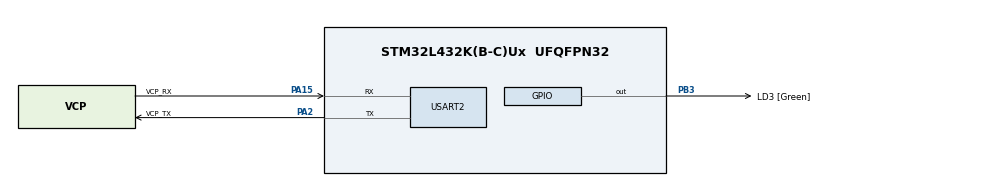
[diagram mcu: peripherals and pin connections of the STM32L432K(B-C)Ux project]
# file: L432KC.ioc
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FREERTOS.Tasks01=defaultTask,0,128,StartDefaultTask,Default,NULL,Dynamic,NULL,NULL;myTask02,-3,128,StartTask02,Default,NULL,Dynamic,NULL,NULL
Mcu.Family=STM32L4
Mcu.Name=STM32L432K(B-C)Ux
Mcu.Package=UFQFPN32
NVIC.PriorityGroup=NVIC_PRIORITYGROUP_4
NVIC.TIM1_UP_TIM16_IRQn=true\:15\:0\:false\:false\:true\:false\:false\:true\:true
NVIC.TimeBase=TIM1_UP_TIM16_IRQn
NVIC.TimeBaseIP=TIM16
NVIC.USART2_IRQn=true\:5\:0\:false\:false\:true\:true\:true\:true\:true
PA0.GPIO_Label=MCO [High speed clock in]
PA0.Mode=HSE-External-Clock-Source-for-LittleOrca
PA0.Signal=RCC_CK_IN
PA13\ (JTMS-SWDIO).GPIO_Label=SWDIO
PA13\ (JTMS-SWDIO).Mode=Serial_Wire
PA13\ (JTMS-SWDIO).Signal=SYS_JTMS-SWDIO
PA14\ (JTCK-SWCLK).GPIO_Label=SWCLK
PA14\ (JTCK-SWCLK).Mode=Serial_Wire
PA14\ (JTCK-SWCLK).Signal=SYS_JTCK-SWCLK
PA15\ (JTDI).GPIO_Label=VCP_RX
PA15\ (JTDI).Mode=Asynchronous
PA15\ (JTDI).Signal=USART2_RX
PA2.GPIO_Label=VCP_TX
PA2.Mode=Asynchronous
PA2.Signal=USART2_TX
PB3\ (JTDO-TRACESWO).GPIO_Label=LD3 [Green]
PB3\ (JTDO-TRACESWO).Signal=GPIO_Output
PC14-OSC32_IN\ (PC14).Mode=LSE-External-Oscillator
PC14-OSC32_IN\ (PC14).Signal=RCC_OSC32_IN
PC15-OSC32_OUT\ (PC15).Mode=LSE-External-Oscillator
PC15-OSC32_OUT\ (PC15).Signal=RCC_OSC32_OUT
ProjectManager.HeapSize=0x200
ProjectManager.StackSize=0x400
ProjectManager.TargetToolchain=Makefile
RCC.AHBFreq_Value=64000000
RCC.APB1Freq_Value=64000000
RCC.APB1TimFreq_Value=64000000
RCC.APB2Freq_Value=64000000
RCC.APB2TimFreq_Value=64000000
RCC.CortexFreq_Value=64000000
RCC.HCLKFreq_Value=64000000
RCC.HSE_VALUE=8000000
RCC.HSI16_VALUE=16000000
RCC.HSI48_VALUE=48000000
RCC.HSI_VALUE=16000000
RCC.MSI_VALUE=4000000
RCC.PLLMUL=RCC_PLLMUL_4
RCC.PLLN=32
RCC.SYSCLKFreq_VALUE=64000000
RCC.SYSCLKSource=RCC_SYSCLKSOURCE_PLLCLK
RCC.VCOOutputFreq_Value=128000000
USART2.VirtualMode-Asynchronous=VM_ASYNC
USART2.WordLength=WORDLENGTH_9B
VP_FREERTOS_VS_CMSIS_V1.Mode=CMSIS_V1
VP_SYS_VS_tim16.Mode=TIM16
board=NUCLEO-L432KC

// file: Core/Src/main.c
/* USER CODE BEGIN Header */
/**
  ******************************************************************************
  * @file           : main.c
  * @brief          : Main program body
  ******************************************************************************
  * @attention
  *
  * Copyright (c) 2023 STMicroelectronics.
  * All rights reserved.
  *
  * This software is licensed under terms that can be found in the LICENSE file
  * in the root directory of this software component.
  * If no LICENSE file comes with this software, it is provided AS-IS.
  *
  ******************************************************************************
  */
/* USER CODE END Header */
#include "main.h"
#include "cmsis_os.h"

/* USER CODE BEGIN Includes */
#include "trice.h"
/* USER CODE END Includes */

osThreadId defaultTaskHandle;
osThreadId myTask02Handle;
/* USER CODE BEGIN PV */
__weak int _close(void) { return -1; }
__weak int _lseek(void) { return -1; }
__weak int _read (void) { return -1; }
__weak int _write(void) { return -1; }
/* USER CODE END PV */

void SystemClock_Config(void);
static void MX_GPIO_Init(void);
static void MX_USART2_UART_Init(void);
void StartDefaultTask(void const * argument);
void StartTask02(void const * argument);

/* USER CODE BEGIN 0 */
volatile uint32_t * const DWT_CONTROL = (uint32_t *) 0xE0001000;
volatile uint32_t * const DWT_CYCCNT = (uint32_t *) 0xE0001004;
volatile uint32_t * const DEMCR = (uint32_t *) 0xE000EDFC;
volatile uint32_t * const LAR  = (uint32_t *) 0xE0001FB0;   // lock access register
/* USER CODE END 0 */

int main(void)
{

  /* USER CODE BEGIN 1 */

*DEMCR = *DEMCR | 0x01000000;     // enable trace
*LAR = 0xC5ACCE55;                // <-- added unlock access to DWT (ITM, etc.)registers
*DWT_CYCCNT = 0;                  // clear DWT cycle counter
*DWT_CONTROL = *DWT_CONTROL | 1;  // enable DWT cycle counter

#if !TRICE_OFF
  TriceInit(); // This so early, to allow trice logs inside interrupts from the beginning.
  TriceHeadLine("  𝕹𝖀𝕮𝕷𝕰𝕺-L432KC   ");
  LogTriceConfiguration();
  SomeExampleTrices(10);
#endif
  /* USER CODE END 1 */

  /* MCU Configuration--------------------------------------------------------*/

  /* Reset of all peripherals, Initializes the Flash interface and the Systick. */
  HAL_Init();

  /* Configure the system clock */
  SystemClock_Config();

  /* Initialize all configured peripherals */
  MX_GPIO_Init();
  MX_USART2_UART_Init();
  /* USER CODE BEGIN 2 */
  SomeExampleTrices(0);
  /* USER CODE END 2 */

  /* Create the thread(s) */
  /* definition and creation of defaultTask */
  osThreadDef(defaultTask, StartDefaultTask, osPriorityNormal, 0, 128);
  defaultTaskHandle = osThreadCreate(osThread(defaultTask), NULL);

  /* definition and creation of myTask02 */
  osThreadDef(myTask02, StartTask02, osPriorityIdle, 0, 128);
  myTask02Handle = osThreadCreate(osThread(myTask02), NULL);

  /* Start scheduler */
  osKernelStart();

  /* We should never get here as control is now taken by the scheduler */

  /* Infinite loop */
  while (1)
  {

  }
}

void SystemClock_Config(void)
{
  LL_FLASH_SetLatency(LL_FLASH_LATENCY_3);
  while(LL_FLASH_GetLatency()!= LL_FLASH_LATENCY_3)
  {
  }
  LL_PWR_SetRegulVoltageScaling(LL_PWR_REGU_VOLTAGE_SCALE1);
  while (LL_PWR_IsActiveFlag_VOS() != 0)
  {
  }
  LL_RCC_MSI_Enable();

   /* Wait till MSI is ready */
  while(LL_RCC_MSI_IsReady() != 1)
  {

  }
  LL_RCC_MSI_EnableRangeSelection();
  LL_RCC_MSI_SetRange(LL_RCC_MSIRANGE_6);
  LL_RCC_MSI_SetCalibTrimming(0);
  LL_PWR_EnableBkUpAccess();
  LL_RCC_LSE_SetDriveCapability(LL_RCC_LSEDRIVE_LOW);
  LL_RCC_LSE_Enable();

   /* Wait till LSE is ready */
  while(LL_RCC_LSE_IsReady() != 1)
  {

  }
  LL_RCC_MSI_EnablePLLMode();
  LL_RCC_PLL_ConfigDomain_SYS(LL_RCC_PLLSOURCE_MSI, LL_RCC_PLLM_DIV_1, 32, LL_RCC_PLLR_DIV_2);
  LL_RCC_PLL_EnableDomain_SYS();
  LL_RCC_PLL_Enable();

   /* Wait till PLL is ready */
  while(LL_RCC_PLL_IsReady() != 1)
  {

  }
  LL_RCC_SetSysClkSource(LL_RCC_SYS_CLKSOURCE_PLL);

   /* Wait till System clock is ready */
  while(LL_RCC_GetSysClkSource() != LL_RCC_SYS_CLKSOURCE_STATUS_PLL)
  {

  }
  LL_RCC_SetAHBPrescaler(LL_RCC_SYSCLK_DIV_1);
  LL_RCC_SetAPB1Prescaler(LL_RCC_APB1_DIV_1);
  LL_RCC_SetAPB2Prescaler(LL_RCC_APB2_DIV_1);
  LL_SetSystemCoreClock(64000000);

   /* Update the time base */
  if (HAL_InitTick (TICK_INT_PRIORITY) != HAL_OK)
  {
    Error_Handler();
  }
}

static void MX_USART2_UART_Init(void)
{

  LL_USART_InitTypeDef USART_InitStruct = {0};

  LL_GPIO_InitTypeDef GPIO_InitStruct = {0};

  LL_RCC_SetUSARTClockSource(LL_RCC_USART2_CLKSOURCE_PCLK1);

  /* Peripheral clock enable */
  LL_APB1_GRP1_EnableClock(LL_APB1_GRP1_PERIPH_USART2);

  LL_AHB2_GRP1_EnableClock(LL_AHB2_GRP1_PERIPH_GPIOA);
  /**USART2 GPIO Configuration
  PA2   ------> USART2_TX
  PA15 (JTDI)   ------> USART2_RX
  */
  GPIO_InitStruct.Pin = VCP_TX_Pin;
  GPIO_InitStruct.Mode = LL_GPIO_MODE_ALTERNATE;
  GPIO_InitStruct.Speed = LL_GPIO_SPEED_FREQ_VERY_HIGH;
  GPIO_InitStruct.OutputType = LL_GPIO_OUTPUT_PUSHPULL;
  GPIO_InitStruct.Pull = LL_GPIO_PULL_NO;
  GPIO_InitStruct.Alternate = LL_GPIO_AF_7;
  LL_GPIO_Init(VCP_TX_GPIO_Port, &GPIO_InitStruct);

  GPIO_InitStruct.Pin = VCP_RX_Pin;
  GPIO_InitStruct.Mode = LL_GPIO_MODE_ALTERNATE;
  GPIO_InitStruct.Speed = LL_GPIO_SPEED_FREQ_VERY_HIGH;
  GPIO_InitStruct.OutputType = LL_GPIO_OUTPUT_PUSHPULL;
  GPIO_InitStruct.Pull = LL_GPIO_PULL_NO;
  GPIO_InitStruct.Alternate = LL_GPIO_AF_3;
  LL_GPIO_Init(VCP_RX_GPIO_Port, &GPIO_InitStruct);

  /* USART2 interrupt Init */
  NVIC_SetPriority(USART2_IRQn, NVIC_EncodePriority(NVIC_GetPriorityGrouping(),5, 0));
  NVIC_EnableIRQ(USART2_IRQn);

  USART_InitStruct.BaudRate = 115200;
  USART_InitStruct.DataWidth = LL_USART_DATAWIDTH_9B;
  USART_InitStruct.StopBits = LL_USART_STOPBITS_1;
  USART_InitStruct.Parity = LL_USART_PARITY_NONE;
  USART_InitStruct.TransferDirection = LL_USART_DIRECTION_TX_RX;
  USART_InitStruct.HardwareFlowControl = LL_USART_HWCONTROL_NONE;
  USART_InitStruct.OverSampling = LL_USART_OVERSAMPLING_16;
  LL_USART_Init(USART2, &USART_InitStruct);
  LL_USART_ConfigAsyncMode(USART2);
  LL_USART_Enable(USART2);

}

static void MX_GPIO_Init(void)
{
  LL_GPIO_InitTypeDef GPIO_InitStruct = {0};

  /* GPIO Ports Clock Enable */
  LL_AHB2_GRP1_EnableClock(LL_AHB2_GRP1_PERIPH_GPIOC);
  LL_AHB2_GRP1_EnableClock(LL_AHB2_GRP1_PERIPH_GPIOA);
  LL_AHB2_GRP1_EnableClock(LL_AHB2_GRP1_PERIPH_GPIOB);

  /**/
  LL_GPIO_ResetOutputPin(LD3_GPIO_Port, LD3_Pin);

  /**/
  GPIO_InitStruct.Pin = LD3_Pin;
  GPIO_InitStruct.Mode = LL_GPIO_MODE_OUTPUT;
  GPIO_InitStruct.Speed = LL_GPIO_SPEED_FREQ_LOW;
  GPIO_InitStruct.OutputType = LL_GPIO_OUTPUT_PUSHPULL;
  GPIO_InitStruct.Pull = LL_GPIO_PULL_NO;
  LL_GPIO_Init(LD3_GPIO_Port, &GPIO_InitStruct);

}

void StartDefaultTask(void const * argument)
{
  /* USER CODE BEGIN 5 */
  TRICE_UNUSED(argument)
  trice("StartDefaultTask\n");
  /* Infinite loop */
  for(;;)
  {
#if !TRICE_OFF
    static int i = 0;
    if( i++ > 2500 ){
      i = 0;
    }
    TriceCheck( i ); // this generates trice data
#endif
    osDelay(10);
  }
  /* USER CODE END 5 */
}

void StartTask02(void const * argument)
{
  /* USER CODE BEGIN StartTask02 */
  TRICE_UNUSED(argument)
  trice("StartTask02\n");
  /* Infinite loop */
  for(;;)
  {
#if !TRICE_OFF
    static int i = 0;
    if( ++i >= 10 ){
      i = 0;
      #if TRICE_DIAGNOSTICS == 1
      TriceLogDiagnosticData();
      #endif
    }
    TriceTransfer();
#endif
    osDelay(100);
  }
  /* USER CODE END StartTask02 */
}

void HAL_TIM_PeriodElapsedCallback(TIM_HandleTypeDef *htim)
{
  if (htim->Instance == TIM16) {
    HAL_IncTick();
  }
}

void Error_Handler(void)
{
  __disable_irq();
  while (1)
  {
  }
}
